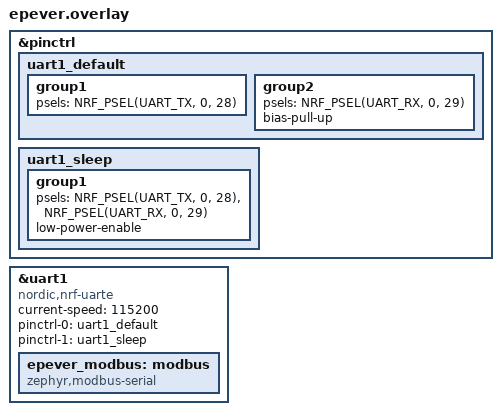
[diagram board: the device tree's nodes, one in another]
/*
 * Epever charge controller on RS-485 (boards/common/epever.conf).
 * UART1 on the pin header: P0.28 = TX -> transceiver DI (its input),
 * P0.29 = RX <- transceiver RO (its output). uart0 stays with the GPS.
 * 115200 8N1, the controller's default.
 */

&pinctrl {
	uart1_default: uart1_default {
		group1 {
			psels = <NRF_PSEL(UART_TX, 0, 28)>;
		};
		group2 {
			psels = <NRF_PSEL(UART_RX, 0, 29)>;
			bias-pull-up;
		};
	};

	uart1_sleep: uart1_sleep {
		group1 {
			psels = <NRF_PSEL(UART_TX, 0, 28)>,
				<NRF_PSEL(UART_RX, 0, 29)>;
			low-power-enable;
		};
	};
};

&uart1 {
	compatible = "nordic,nrf-uarte";
	status = "okay";
	current-speed = <115200>;
	pinctrl-0 = <&uart1_default>;
	pinctrl-1 = <&uart1_sleep>;
	pinctrl-names = "default", "sleep";

	epever_modbus: modbus {
		compatible = "zephyr,modbus-serial";
		status = "okay";
	};
};
